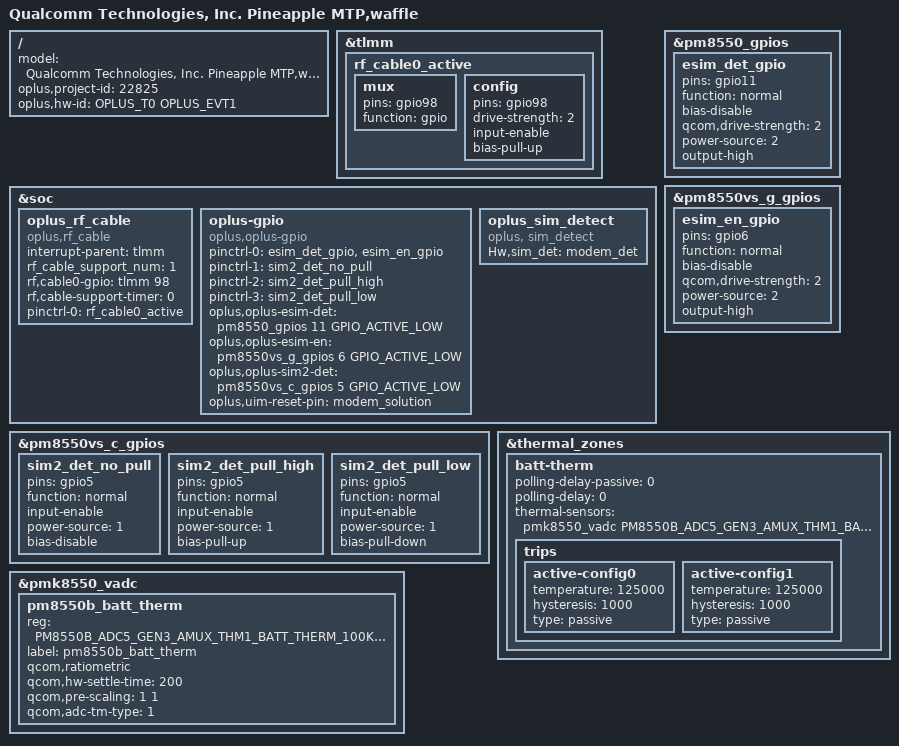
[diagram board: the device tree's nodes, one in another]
/dts-v1/;
/plugin/;
#include <dt-bindings/oplus/hw-id.h>
#include "../qcom/pineapple-mtp-overlay.dts"
#include "pineapple_overlay_common.dtsi"
#include "waffle_overlay_common.dtsi"
#include "oplus_chg/oplus-chg-22825-EVT1.dtsi"
#include "oplus_misc/oplus-misc-22825.dtsi"
#include "sensor/waffle-sensor-22825.dtsi"
#include "tp/waffle-oplus-tp-22825.dtsi"
#include "oplus_fp/oplus_fp_22825.dtsi"

/ {
    model = "Qualcomm Technologies, Inc. Pineapple MTP,waffle";

    oplus,project-id = <22825>;
    oplus,hw-id = <OPLUS_T0 OPLUS_EVT1>;
};

&tlmm {
  //#ifdef OPLUS_FEATURE_RF_CABLE_DETECT
  rf_cable0_active: rf_cable0_active {
    mux {
      pins = "gpio98";
      function = "gpio";
    };
    config {
      pins = "gpio98";
      drive-strength = <2>;
      input-enable;
      bias-pull-up;
    };
  };
  //#endif /* OPLUS_FEATURE_RF_CABLE_DETECT */
};

&soc {
  //#ifdef OPLUS_FEATURE_RF_CABLE_DETECT
  oplus_rf_cable {
    compatible = "oplus,rf_cable";
    interrupt-parent = <&tlmm>;
    rf_cable_support_num = <1>;
    rf,cable0-gpio = <&tlmm 98 0>;
    rf,cable-support-timer = <0>;
    pinctrl-names = "rf_cable_active";
    pinctrl-0 = <&rf_cable0_active>;
  };
  //#endif /* OPLUS_FEATURE_RF_CABLE_DETECT */

  //#ifdef OPLUS_FEATURE_ESIM
  oplus-gpio {
    compatible = "oplus,oplus-gpio";
    pinctrl-names = "oplus_esim", "sim2_det_no_pull", "sim2_det_pull_high", "sim2_det_pull_low";
    pinctrl-0 = <&esim_det_gpio &esim_en_gpio>;
    pinctrl-1 = <&sim2_det_no_pull>;
    pinctrl-2 = <&sim2_det_pull_high>;
    pinctrl-3 = <&sim2_det_pull_low>;
    oplus,oplus-esim-det = <&pm8550_gpios 11 GPIO_ACTIVE_LOW>;
    oplus,oplus-esim-en = <&pm8550vs_g_gpios 6 GPIO_ACTIVE_LOW>;
    oplus,oplus-sim2-det = <&pm8550vs_c_gpios 5 GPIO_ACTIVE_LOW>;
    oplus,uim-reset-pin = "modem_solution";
  };
  oplus_sim_detect {
    compatible = "oplus, sim_detect";
    Hw,sim_det = "modem_det";
  };
  //#endif /*OPLUS_FEATURE_ESIM*/
};

&pm8550_gpios {
  esim_det_gpio: esim_det_gpio {
      pins = "gpio11";
      function = "normal";
      bias-disable; /* NO pull */
      qcom,drive-strength = <2>; /* 2 MA */
      power-source = <2>; /* 1.2V */
      output-high;
  };
};

&pm8550vs_g_gpios {
  esim_en_gpio: esim_en_gpio  {
      pins = "gpio6";
      function = "normal";
      bias-disable; /* NO pull */
      qcom,drive-strength = <2>; /* 2 MA */
      power-source = <2>; /* 1.2V */
      output-high;
  };
};

&pm8550vs_c_gpios {
  sim2_det_no_pull: sim2_det_no_pull {
      pins = "gpio5";
      function = "normal";
      input-enable;
      power-source = <1>;
      bias-disable;
  };

  sim2_det_pull_high: sim2_det_pull_high {
      pins = "gpio5";
      function = "normal";
      input-enable;
      power-source = <1>;
      bias-pull-up;
  };

  sim2_det_pull_low: sim2_det_pull_low {
      pins = "gpio5";
      function = "normal";
      input-enable;
      power-source = <1>;
      bias-pull-down;
  };
};

&pmk8550_vadc {
	pm8550b_batt_therm {
		reg = <PM8550B_ADC5_GEN3_AMUX_THM1_BATT_THERM_100K_PU>;
		label = "pm8550b_batt_therm";
		qcom,ratiometric;
		qcom,hw-settle-time = <200>;
		qcom,pre-scaling = <1 1>;
		qcom,adc-tm-type = <1>;
	};
};

&thermal_zones {
	batt-therm {
		polling-delay-passive = <0>;
		polling-delay = <0>;
		thermal-sensors = <&pmk8550_vadc PM8550B_ADC5_GEN3_AMUX_THM1_BATT_THERM_100K_PU>;
		trips {
			active-config0 {
				temperature = <125000>;
				hysteresis = <1000>;
				type = "passive";
			};

			active-config1 {
				temperature = <125000>;
				hysteresis = <1000>;
				type = "passive";
			};
		};
	};
};
